VERSION ""

NS_ :

BS_:

BU_: INERTIAL_MEASUREMENT_UNIT SENSOR_CONTROL_UNIT VEHICLE_CONTORL_UNIT ACCUMULATOR_CONTROL_UNIT MOTOR_CONTROLLER EMUS_BMS
VAL_TABLE_ SWITCH_TOGGLE 1 "TRUE/ON" 0 "FALSE/OFF" ;
VAL_TABLE_ MC_BUS_STATE 1 "CHARGED" 0 "DISCHARGED'" ;
VAL_TABLE_ SET_INVERTER_DISCHARGE 1 "ENABLED" 0 "DISABLED" ;
VAL_TABLE_ SET_INVERTER_ENABLE 1 "ENABLED" 0 "DISABLED" ;
VAL_TABLE_ SET_MC_DIRECTION 1 "FORWARD" 0 "REVERSE" ;
VAL_TABLE_ DriveState 0 "DriveDisabled" ;

BO_ 3221225472 VECTOR__INDEPENDENT_SIG_MSG: 0 Vector__XXX
 SG_ MC_PARAM_COMMAND : 0|8@1- (1,0) [0|0] "" Vector__XXX

BO_ 1549 CAN_ENERGY_METER_TEMPERATURE: 8 SENSOR_CONTROL_UNIT

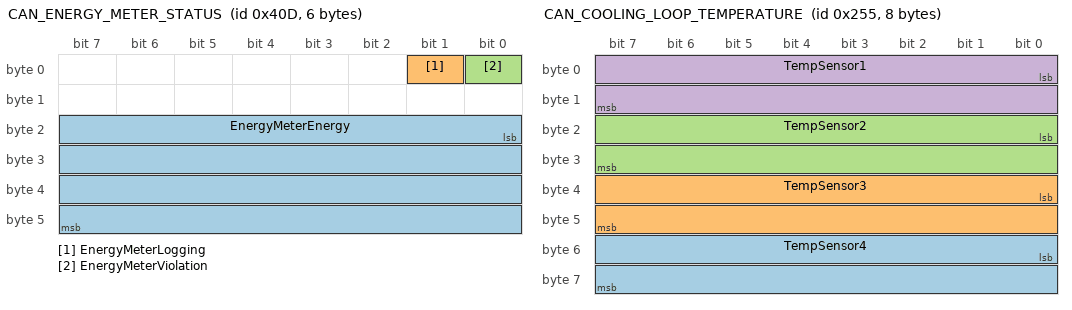
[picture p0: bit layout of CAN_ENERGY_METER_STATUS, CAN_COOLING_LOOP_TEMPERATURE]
BO_ 1037 CAN_ENERGY_METER_STATUS: 6 SENSOR_CONTROL_UNIT
 SG_ EnergyMeterEnergy : 16|32@1+ (1,0) [0|4294967295] "Whr" Vector__XXX
 SG_ EnergyMeterLogging : 1|1@1+ (1,0) [0|1] "" Vector__XXX
 SG_ EnergyMeterViolation : 0|1@1+ (1,0) [0|1] "" Vector__XXX

BO_ 269 CAN_ENERGY_METER_MEASUREMENT_MSG: 8 SENSOR_CONTROL_UNIT
 SG_ EnergyMeterVoltage : 39|32@0- (1,0) [-2147483648|2147483647] "V" Vector__XXX
 SG_ EnergyMeterCurrent : 7|32@0- (1,0) [-2147483648|2147483647] "A" Vector__XXX

BO_ 598 CAN_FLOW_METER: 2 SENSOR_CONTROL_UNIT
 SG_ FlowRate : 0|16@1+ (0.01,0) [0|655.35] "L/s" Vector__XXX

BO_ 597 CAN_COOLING_LOOP_TEMPERATURE: 8 SENSOR_CONTROL_UNIT
 SG_ TempSensor4 : 48|16@1- (0.01,0) [-327.68|327.67] "degC" Vector__XXX
 SG_ TempSensor3 : 32|16@1- (0.01,0) [-327.68|327.67] "degC" Vector__XXX
 SG_ TempSensor2 : 16|16@1- (0.01,0) [-327.68|327.67] "degC" Vector__XXX
 SG_ TempSensor1 : 0|16@1- (0.01,0) [-327.68|327.67] "degC" Vector__XXX

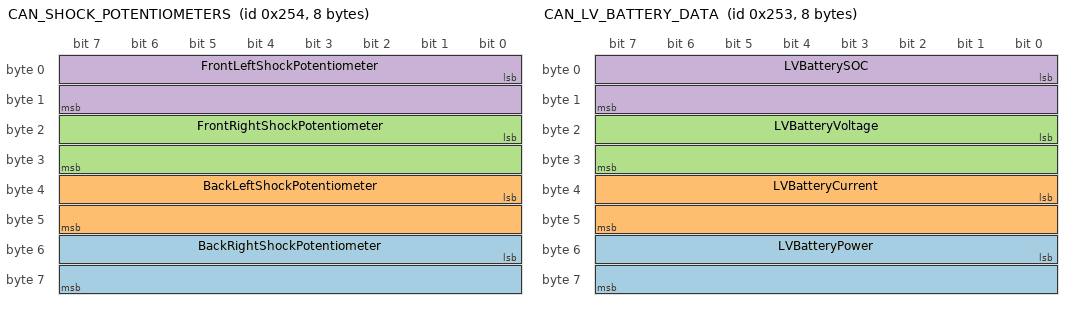
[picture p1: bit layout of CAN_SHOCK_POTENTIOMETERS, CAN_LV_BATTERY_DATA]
BO_ 596 CAN_SHOCK_POTENTIOMETERS: 8 SENSOR_CONTROL_UNIT
 SG_ BackRightShockPotentiometer : 48|16@1+ (0.01,0) [0|655.35] "mm" Vector__XXX
 SG_ BackLeftShockPotentiometer : 32|16@1+ (0.01,0) [0|655.35] "mm" Vector__XXX
 SG_ FrontRightShockPotentiometer : 16|16@1+ (0.01,0) [0|655.35] "mm" Vector__XXX
 SG_ FrontLeftShockPotentiometer : 0|16@1+ (0.01,0) [0|655.35] "mm" Vector__XXX

BO_ 595 CAN_LV_BATTERY_DATA: 8 SENSOR_CONTROL_UNIT
 SG_ LVBatteryPower : 48|16@1+ (0.01,0) [0|655.35] "W" Vector__XXX
 SG_ LVBatteryCurrent : 32|16@1- (0.01,0) [-327.68|327.67] "A" Vector__XXX
 SG_ LVBatteryVoltage : 16|16@1- (0.01,0) [-327.68|327.67] "V" Vector__XXX
 SG_ LVBatterySOC : 0|16@1+ (0.01,0) [0|655.35] "%" Vector__XXX

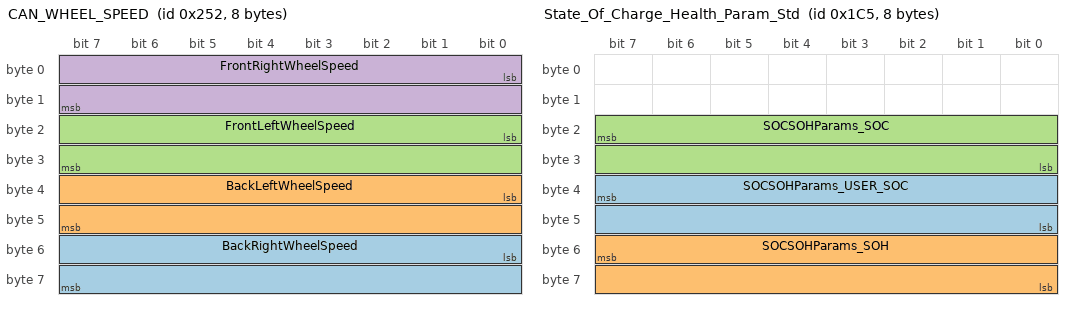
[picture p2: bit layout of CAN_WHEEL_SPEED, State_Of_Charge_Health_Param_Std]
BO_ 594 CAN_WHEEL_SPEED: 8 SENSOR_CONTROL_UNIT
 SG_ BackRightWheelSpeed : 48|16@1- (0.01,0) [-327.68|327.67] "kph" Vector__XXX
 SG_ BackLeftWheelSpeed : 32|16@1- (0.01,0) [-327.68|327.67] "kph" Vector__XXX
 SG_ FrontLeftWheelSpeed : 16|16@1- (0.01,0) [-327.68|327.67] "kph" Vector__XXX
 SG_ FrontRightWheelSpeed : 0|16@1- (0.01,0) [-327.68|327.67] "kph" Vector__XXX

BO_ 593 CAN_VEHICLE_SPEED: 2 SENSOR_CONTROL_UNIT
 SG_ Vehicle_Speed : 0|16@1- (0.01,0) [-327.68|327.67] "kph" Vector__XXX

BO_ 573 Charger_Control_Std: 1 SENSOR_CONTROL_UNIT
 SG_ Charger_Control : 7|8@0- (1,0) [0|2] "" Vector__XXX

BO_ 2578777096 Charger_Control_Ext: 1 SENSOR_CONTROL_UNIT
 SG_ Charger_Control : 7|8@0- (1,0) [0|2] "" Vector__XXX

BO_ 453 State_Of_Charge_Health_Param_Std: 8 SENSOR_CONTROL_UNIT
 SG_ SOCSOHParams_USER_SOC : 39|16@0+ (0.01,0) [0|655.35] "%" Vector__XXX
 SG_ SOCSOHParams_SOH : 55|16@0+ (0.01,0) [0|655.35] "%" Vector__XXX
 SG_ SOCSOHParams_SOC : 23|16@0+ (0.01,0) [0|655.35] "%" Vector__XXX

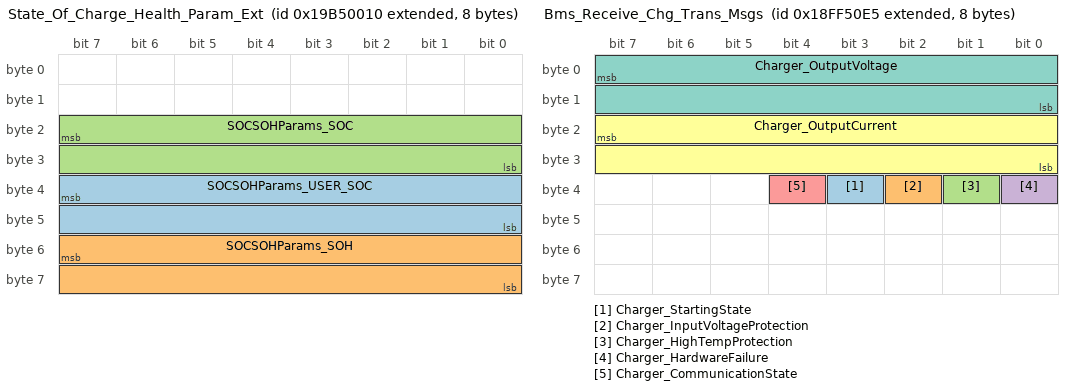
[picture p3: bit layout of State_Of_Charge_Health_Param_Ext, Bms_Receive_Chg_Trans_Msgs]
BO_ 2578776080 State_Of_Charge_Health_Param_Ext: 8 SENSOR_CONTROL_UNIT
 SG_ SOCSOHParams_USER_SOC : 39|16@0+ (0.01,0) [0|655.35] "%" Vector__XXX
 SG_ SOCSOHParams_SOH : 55|16@0+ (0.01,0) [0|655.35] "%" Vector__XXX
 SG_ SOCSOHParams_SOC : 23|16@0+ (0.01,0) [0|655.35] "%" Vector__XXX

BO_ 2566869221 Bms_Receive_Chg_Trans_Msgs: 8 SENSOR_CONTROL_UNIT
 SG_ Charger_StartingState : 35|1@0+ (1,0) [0|1] "" Vector__XXX
 SG_ Charger_InputVoltageProtection : 34|1@0+ (1,0) [0|1] "" Vector__XXX
 SG_ Charger_HighTempProtection : 33|1@0+ (1,0) [0|1] "" Vector__XXX
 SG_ Charger_HardwareFailure : 32|1@0+ (1,0) [0|1] "" Vector__XXX
 SG_ Charger_CommunicationState : 36|1@0+ (1,0) [0|1] "" Vector__XXX
 SG_ Charger_OutputCurrent : 23|16@0+ (0.1,0) [0|65535.01] "A" Vector__XXX
 SG_ Charger_OutputVoltage : 7|16@0+ (0.1,0) [0|65535.01] "V" Vector__XXX

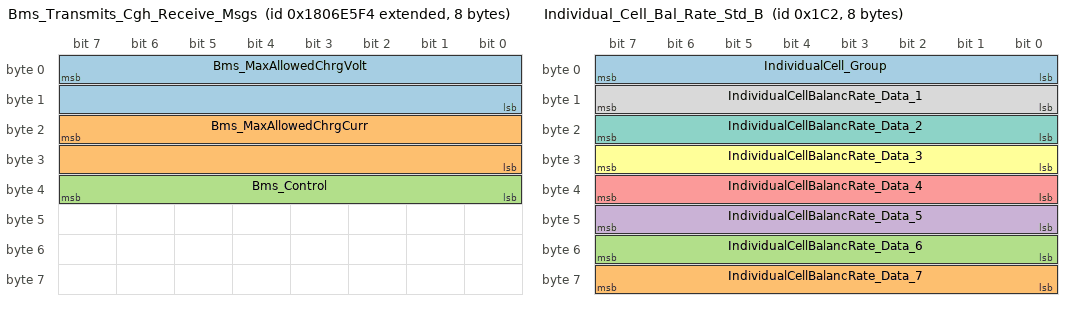
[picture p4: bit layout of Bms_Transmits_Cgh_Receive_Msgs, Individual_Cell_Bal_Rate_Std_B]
BO_ 2550588916 Bms_Transmits_Cgh_Receive_Msgs: 8 SENSOR_CONTROL_UNIT
 SG_ Bms_MaxAllowedChrgVolt : 7|16@0+ (0.1,0) [0|65535.01] "V" Vector__XXX
 SG_ Bms_MaxAllowedChrgCurr : 23|16@0+ (0.1,0) [0|65535.01] "A" Vector__XXX
 SG_ Bms_Control : 39|8@0+ (1,0) [0|1] "" Vector__XXX

BO_ 450 Individual_Cell_Bal_Rate_Std_B: 8 SENSOR_CONTROL_UNIT
 SG_ IndividualCell_Group : 7|8@0+ (1,0) [0|255] "" Vector__XXX
 SG_ IndividualCellBalancRate_Data_7 : 63|8@0+ (0.392156862745098,0) [0|100] "%" Vector__XXX
 SG_ IndividualCellBalancRate_Data_6 : 55|8@0+ (0.392156862745098,0) [0|100] "%" Vector__XXX
 SG_ IndividualCellBalancRate_Data_5 : 47|8@0+ (0.392156862745098,0) [0|100] "%" Vector__XXX
 SG_ IndividualCellBalancRate_Data_4 : 39|8@0+ (0.392156862745098,0) [0|100] "%" Vector__XXX
 SG_ IndividualCellBalancRate_Data_3 : 31|8@0+ (0.392156862745098,0) [0|100] "%" Vector__XXX
 SG_ IndividualCellBalancRate_Data_2 : 23|8@0+ (0.392156862745098,0) [0|100] "%" Vector__XXX
 SG_ IndividualCellBalancRate_Data_1 : 15|8@0+ (0.392156862745098,0) [0|100] "%" Vector__XXX

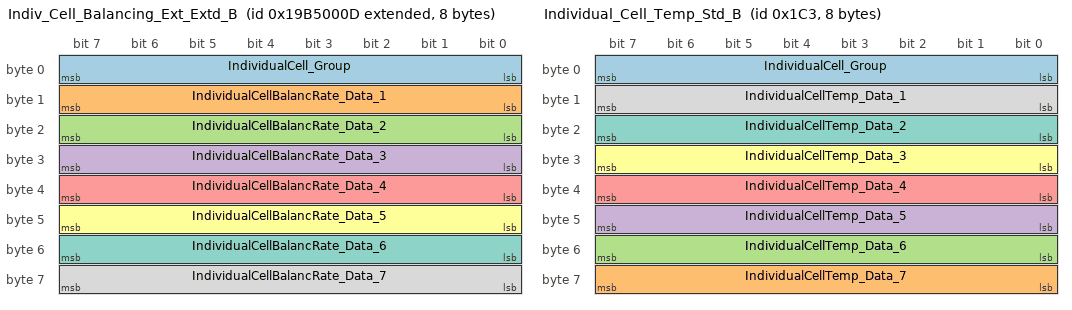
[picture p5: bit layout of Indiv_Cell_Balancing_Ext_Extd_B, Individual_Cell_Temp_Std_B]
BO_ 2578776077 Indiv_Cell_Balancing_Ext_Extd_B: 8 SENSOR_CONTROL_UNIT
 SG_ IndividualCell_Group : 7|8@0+ (1,0) [0|255] "" Vector__XXX
 SG_ IndividualCellBalancRate_Data_1 : 15|8@0+ (0.392156862745098,0) [0|100] "%" Vector__XXX
 SG_ IndividualCellBalancRate_Data_2 : 23|8@0+ (0.392156862745098,0) [0|100] "%" Vector__XXX
 SG_ IndividualCellBalancRate_Data_3 : 31|8@0+ (0.392156862745098,0) [0|100] "%" Vector__XXX
 SG_ IndividualCellBalancRate_Data_4 : 39|8@0+ (0.392156862745098,0) [0|100] "%" Vector__XXX
 SG_ IndividualCellBalancRate_Data_5 : 47|8@0+ (0.392156862745098,0) [0|100] "%" Vector__XXX
 SG_ IndividualCellBalancRate_Data_6 : 55|8@0+ (0.392156862745098,0) [0|100] "%" Vector__XXX
 SG_ IndividualCellBalancRate_Data_7 : 63|8@0+ (0.392156862745098,0) [0|100] "%" Vector__XXX

BO_ 451 Individual_Cell_Temp_Std_B: 8 SENSOR_CONTROL_UNIT
 SG_ IndividualCell_Group : 7|8@0+ (1,0) [0|255] "" Vector__XXX
 SG_ IndividualCellTemp_Data_7 : 63|8@0+ (1,-100) [-100|155] "�C" Vector__XXX
 SG_ IndividualCellTemp_Data_6 : 55|8@0+ (1,-100) [-100|155] "�C" Vector__XXX
 SG_ IndividualCellTemp_Data_5 : 47|8@0+ (1,-100) [-100|155] "�C" Vector__XXX
 SG_ IndividualCellTemp_Data_4 : 39|8@0+ (1,-100) [-100|155] "�C" Vector__XXX
 SG_ IndividualCellTemp_Data_3 : 31|8@0+ (1,-100) [-100|155] "�C" Vector__XXX
 SG_ IndividualCellTemp_Data_2 : 23|8@0+ (1,-100) [-100|155] "�C" Vector__XXX
 SG_ IndividualCellTemp_Data_1 : 15|8@0+ (1,-100) [-100|155] "�C" Vector__XXX

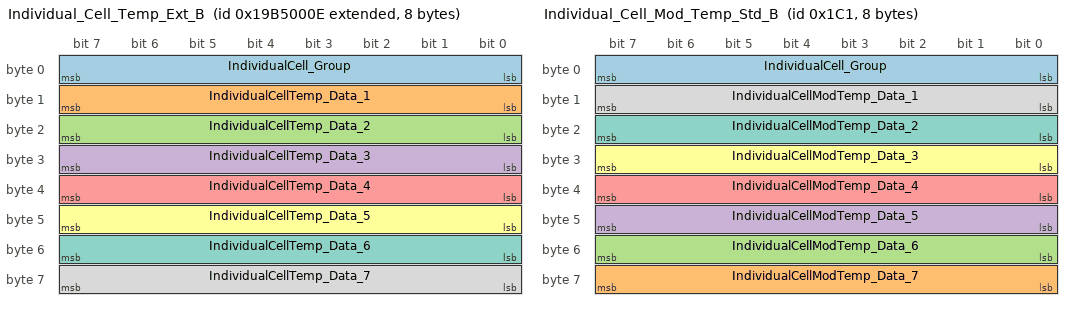
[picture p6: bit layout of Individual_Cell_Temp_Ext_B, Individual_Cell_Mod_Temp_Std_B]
BO_ 2578776078 Individual_Cell_Temp_Ext_B: 8 SENSOR_CONTROL_UNIT
 SG_ IndividualCell_Group : 7|8@0+ (1,0) [0|255] "" Vector__XXX
 SG_ IndividualCellTemp_Data_1 : 15|8@0+ (1,-100) [-100|155] "�C" Vector__XXX
 SG_ IndividualCellTemp_Data_2 : 23|8@0+ (1,-100) [-100|155] "�C" Vector__XXX
 SG_ IndividualCellTemp_Data_3 : 31|8@0+ (1,-100) [-100|155] "�C" Vector__XXX
 SG_ IndividualCellTemp_Data_4 : 39|8@0+ (1,-100) [-100|155] "�C" Vector__XXX
 SG_ IndividualCellTemp_Data_5 : 47|8@0+ (1,-100) [-100|155] "�C" Vector__XXX
 SG_ IndividualCellTemp_Data_6 : 55|8@0+ (1,-100) [-100|155] "�C" Vector__XXX
 SG_ IndividualCellTemp_Data_7 : 63|8@0+ (1,-100) [-100|155] "�C" Vector__XXX

BO_ 449 Individual_Cell_Mod_Temp_Std_B: 8 SENSOR_CONTROL_UNIT
 SG_ IndividualCell_Group : 7|8@0+ (1,0) [0|255] "" Vector__XXX
 SG_ IndividualCellModTemp_Data_7 : 63|8@0+ (1,-100) [-100|155] "�C" Vector__XXX
 SG_ IndividualCellModTemp_Data_6 : 55|8@0+ (1,-100) [-100|155] "�C" Vector__XXX
 SG_ IndividualCellModTemp_Data_5 : 47|8@0+ (1,-100) [-100|155] "�C" Vector__XXX
 SG_ IndividualCellModTemp_Data_4 : 39|8@0+ (1,-100) [-100|155] "�C" Vector__XXX
 SG_ IndividualCellModTemp_Data_3 : 31|8@0+ (1,-100) [-100|155] "�C" Vector__XXX
 SG_ IndividualCellModTemp_Data_2 : 23|8@0+ (1,-100) [-100|155] "�C" Vector__XXX
 SG_ IndividualCellModTemp_Data_1 : 15|8@0+ (1,-100) [-100|155] "�C" Vector__XXX

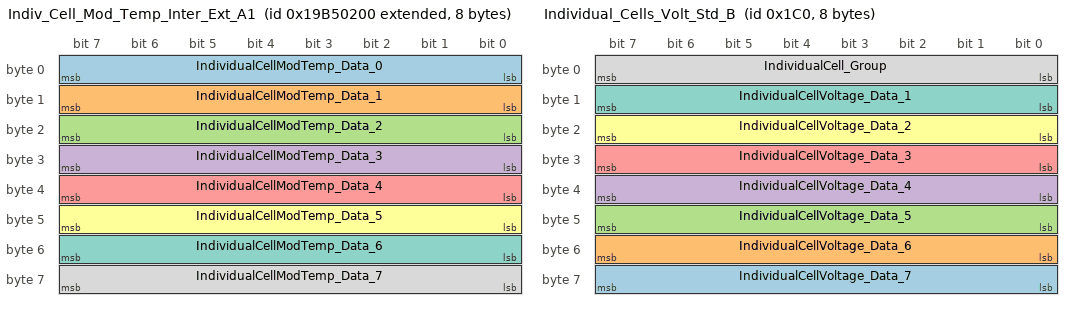
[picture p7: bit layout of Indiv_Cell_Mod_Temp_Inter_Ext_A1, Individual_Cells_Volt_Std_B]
BO_ 2578776576 Indiv_Cell_Mod_Temp_Inter_Ext_A1: 8 SENSOR_CONTROL_UNIT
 SG_ IndividualCellModTemp_Data_0 : 7|8@0+ (1,-100) [-100|155] "�C" Vector__XXX
 SG_ IndividualCellModTemp_Data_1 : 15|8@0+ (1,-100) [-100|155] "�C" Vector__XXX
 SG_ IndividualCellModTemp_Data_2 : 23|8@0+ (1,-100) [-100|155] "�C" Vector__XXX
 SG_ IndividualCellModTemp_Data_3 : 31|8@0+ (1,-100) [-100|155] "�C" Vector__XXX
 SG_ IndividualCellModTemp_Data_4 : 39|8@0+ (1,-100) [-100|155] "�C" Vector__XXX
 SG_ IndividualCellModTemp_Data_5 : 47|8@0+ (1,-100) [-100|155] "�C" Vector__XXX
 SG_ IndividualCellModTemp_Data_6 : 55|8@0+ (1,-100) [-100|155] "�C" Vector__XXX
 SG_ IndividualCellModTemp_Data_7 : 63|8@0+ (1,-100) [-100|155] "�C" Vector__XXX

BO_ 448 Individual_Cells_Volt_Std_B: 8 SENSOR_CONTROL_UNIT
 SG_ IndividualCellVoltage_Data_7 : 63|8@0+ (0.01,2) [2|4.55] "V" Vector__XXX
 SG_ IndividualCellVoltage_Data_6 : 55|8@0+ (0.01,2) [2|4.55] "V" Vector__XXX
 SG_ IndividualCellVoltage_Data_5 : 47|8@0+ (0.01,2) [2|4.55] "V" Vector__XXX
 SG_ IndividualCellVoltage_Data_4 : 39|8@0+ (0.01,2) [2|4.55] "V" Vector__XXX
 SG_ IndividualCellVoltage_Data_3 : 31|8@0+ (0.01,2) [2|4.55] "V" Vector__XXX
 SG_ IndividualCellVoltage_Data_2 : 23|8@0+ (0.01,2) [2|4.55] "V" Vector__XXX
 SG_ IndividualCellVoltage_Data_1 : 15|8@0+ (0.01,2) [2|4.55] "V" Vector__XXX
 SG_ IndividualCell_Group : 7|8@0+ (1,0) [0|255] "" Vector__XXX

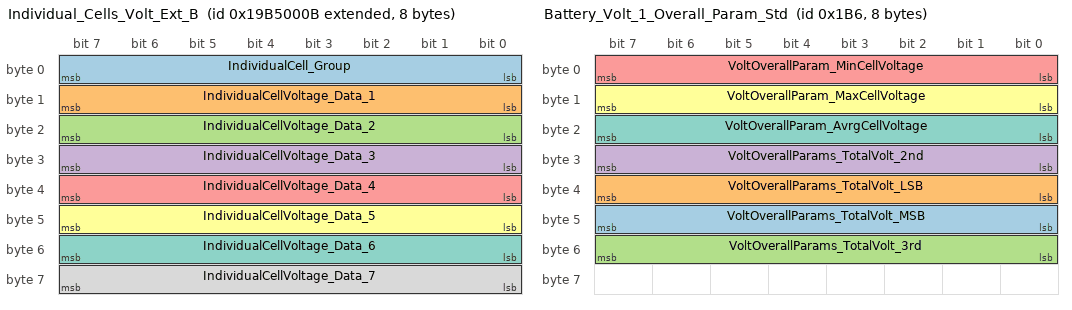
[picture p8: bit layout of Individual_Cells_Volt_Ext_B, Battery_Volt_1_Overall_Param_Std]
BO_ 2578776075 Individual_Cells_Volt_Ext_B: 8 SENSOR_CONTROL_UNIT
 SG_ IndividualCell_Group : 7|8@0+ (1,0) [0|255] "" Vector__XXX
 SG_ IndividualCellVoltage_Data_1 : 15|8@0+ (0.01,2) [2|4.55] "V" Vector__XXX
 SG_ IndividualCellVoltage_Data_2 : 23|8@0+ (0.01,2) [2|4.55] "V" Vector__XXX
 SG_ IndividualCellVoltage_Data_3 : 31|8@0+ (0.01,2) [2|4.55] "V" Vector__XXX
 SG_ IndividualCellVoltage_Data_4 : 39|8@0+ (0.01,2) [2|4.55] "V" Vector__XXX
 SG_ IndividualCellVoltage_Data_5 : 47|8@0+ (0.01,2) [2|4.55] "V" Vector__XXX
 SG_ IndividualCellVoltage_Data_6 : 55|8@0+ (0.01,2) [2|4.55] "V" Vector__XXX
 SG_ IndividualCellVoltage_Data_7 : 63|8@0+ (0.01,2) [2|4.55] "V" Vector__XXX

BO_ 438 Battery_Volt_1_Overall_Param_Std: 8 SENSOR_CONTROL_UNIT
 SG_ VoltOverallParams_TotalVolt_MSB : 47|8@0+ (1,0) [0|255] "" Vector__XXX
 SG_ VoltOverallParams_TotalVolt_LSB : 39|8@0+ (1,0) [0|255] "" Vector__XXX
 SG_ VoltOverallParams_TotalVolt_3rd : 55|8@0+ (1,0) [0|255] "" Vector__XXX
 SG_ VoltOverallParams_TotalVolt_2nd : 31|8@0+ (1,0) [0|255] "" Vector__XXX
 SG_ VoltOverallParam_MinCellVoltage : 7|8@0+ (0.01,2) [2|4.55] "V" Vector__XXX
 SG_ VoltOverallParam_MaxCellVoltage : 15|8@0+ (0.01,2) [2|4.55] "V" Vector__XXX
 SG_ VoltOverallParam_AvrgCellVoltage : 23|8@0+ (0.01,2) [2|4.55] "V" Vector__XXX

BO_ 441 Overall_Parameters2_Std: 8 SENSOR_CONTROL_UNIT
 SG_ OverallParams2_NumberOfCells : 7|16@0+ (1,0) [0|65535] "" Vector__XXX

BO_ 2578776068 Overall_Parameters2_Ext: 8 SENSOR_CONTROL_UNIT
 SG_ OverallParams2_NumberOfCells : 7|16@0+ (1,0) [0|65535] "" Vector__XXX

CM_ BO_ 3221225472 "This is a message for not used signals, created by Vector CANdb++ DBC OLE DB Provider.";
CM_ BO_ 450 "Individual Cell Balancing Rates Standard Option A";
CM_ BO_ 2578776077 "Individual Cell Balancing Rate Extended Option A";
CM_ BO_ 451 "Individual Cell Temperatures Standard Option A";
CM_ BO_ 2578776078 "Individual Cell Temperatures Extended Option A";
CM_ BO_ 449 "Individual Cell Module Temperature Standard Option A";
CM_ BO_ 2578776576 "Individual Cell Module Temperatures Extended Option A";
CM_ BO_ 2578776075 "Individual Cells Voltages Extended Option A";
BA_DEF_  "BusType" STRING ;
BA_DEF_DEF_  "BusType" "CAN";
VAL_ 573 Charger_Control 2 "REQUEST_FOR_STATE" 1 "CHARGING_ENABLED" 0 "CHARGING_DISABLED" ;
VAL_ 2578777096 Charger_Control 2 "REQUEST_FOR_STATE" 1 "CHARGING_ENABLED" 0 "CHARGING_DISABLED" ;
VAL_ 2566869221 Charger_StartingState 1 "Bat Disconnecting Or Reverse" 0 "Normal" ;
VAL_ 2566869221 Charger_InputVoltageProtection 1 "Incrrt Input V/Chrg Stop Working" 0 "Normal" ;
VAL_ 2566869221 Charger_HighTempProtection 1 "Over Temperature Protection" 0 "Normal" ;
VAL_ 2566869221 Charger_HardwareFailure 1 "Hardware Failure" 0 "Normal" ;
VAL_ 2566869221 Charger_CommunicationState 1 "Comm Receiving Time-out" 0 "Normal" ;
VAL_ 2550588916 Bms_Control 1 "Stop Charging" 0 "Start Charging" ;
